# G32R501 register map
Vendor: Geehy Semiconductor Co., Ltd.; Series: G32R5; File version: 1.0
CPU: CM55 r0p1, little endian, MPU, FPU, double-precision FPU, DSP, VTOR, 4 interrupt priority bits
Registers are 32-bit, read-write, reset 0x0 unless marked. A register's access mark holds for its fields unless they carry their own. Offsets are from the block's base; [hi:lo] are bit positions; {n}, {i} and the like mark numbered series.

## FLB1_DATAEXCH — FLB_DATA_EXCHANGE_REGS Registers
Base 0x50102400
Same registers: FLB2_DATAEXCH 0x50102C00, FLB3_DATAEXCH 0x50103400, FLB4_DATAEXCH 0x50103C00
0x00 FLB_PUSH1 ro — FLB PUSH FIFO Registers (from HLC)
  [31:0] PUSH
0x04 FLB_PUSH2 ro — FLB PUSH FIFO Registers (from HLC)
  [31:0] PUSH
0x08 FLB_PUSH3 ro — FLB PUSH FIFO Registers (from HLC)
  [31:0] PUSH
0x0C FLB_PUSH4 ro — FLB PUSH FIFO Registers (from HLC)
  [31:0] PUSH
{0x1FC+4i} FLB_PULL{i} (i=1..4) — FLB PULL FIFO Registers (TO HLC)
  [31:0] PULL

## TMR0 — Timer
Base 0x50110000
Same registers: TMR1 0x50110400, TMR2 0x50110800
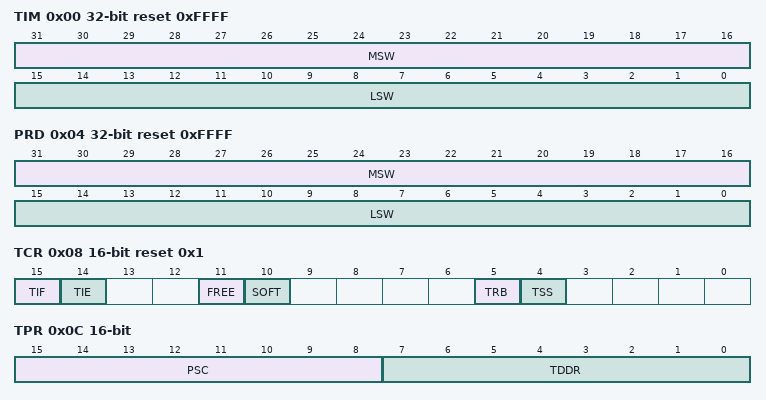
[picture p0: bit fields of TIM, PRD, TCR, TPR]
0x00 TIM reset 0xFFFF — Timer Counter Register
  [31:16] MSW — Timer Counter Registers
  [15:0] LSW — Timer Counter Registers
0x04 PRD reset 0xFFFF — Timer Period Register
  [31:16] MSW — Timer Period Registers
  [15:0] LSW — Timer Period Registers
0x08 TCR 16-bit reset 0x1 — Timer Control Register
  [15] TIF — Timer Overflow Flag
  [14] TIE — Timer Interrupt Enable
  [11] FREE — Emulation modes bit
  [10] SOFT — Emulation modes bit
  [5] TRB — Timer reload
  [4] TSS — Timer stop status bit
0x0C TPR 16-bit access per field — Timer Prescale Register Low
  [15:8] PSC ro — Timer Prescale Counter
  [7:0] TDDR rw — Timer Divide-Down
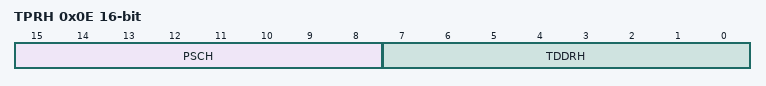
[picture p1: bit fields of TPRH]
0x0E TPRH 16-bit access per field — Timer Prescale Register High
  [15:8] PSCH ro — Timer Prescale Counter
  [7:0] TDDRH rw — Timer Divide-Down

## ADCARESULT — Analog-to-digital converter
Base 0x40020100
Same registers: ADCBRESULT 0x40020500, ADCCRESULT 0x40020900
{0x0+2i} ADCRESULT{i} 16-bit ro (i=0..15)
  [15:0] RESULT — ADC Result {i}
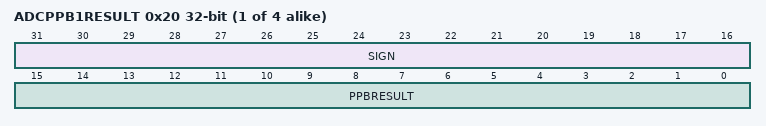
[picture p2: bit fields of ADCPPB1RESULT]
{0x1C+4i} ADCPPB{i}RESULT ro (i=1..4) — ADC Post Processing Block {i} Result Register
  [31:16] SIGN — Sign Extended Bits
  [15:0] PPBRESULT — ADC Post Processing Block Result {i}

## DACA — DAC
Base 0x50001800
Same registers: DACB 0x50001C00
0x00 DACREV 16-bit ro — DAC Revision Register
  [7:0] REV — DAC Revision
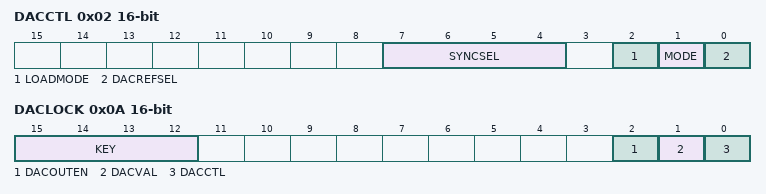
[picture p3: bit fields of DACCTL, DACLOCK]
0x02 DACCTL 16-bit — DAC Control Register
  [7:4] SYNCSEL — DAC EPWMSYNCPER Select
  [2] LOADMODE — DACVALA Load Mode
  [1] MODE — DAC Mode Select
  [0] DACREFSEL — DAC Reference Select
0x04 DACVALA 16-bit ro — DAC Value Register - Active
  [11:0] DACVALA — DAC Active Output Code
0x06 DACVALS 16-bit — DAC Value Register - Shadow
  [11:0] DACVALS — DAC Shadow Output Code
0x08 DACOUTEN 16-bit — DAC Output Enable Register
  [0] DACOUTEN — DAC Output Enable
0x0A DACLOCK 16-bit
  [15:12] KEY — DAC Register Lock Key
  [2] DACOUTEN — DAC Output Enable Register Lock
  [1] DACVAL — DAC Value Register Lock
  [0] DACCTL — DAC Control Register Lock
0x0C DACTRIM 16-bit
  [7:0] OFFSETTRIM — DAC Offset Trim

## SPIA — SPI
Base 0x50001000
Same registers: SPIB 0x50100400
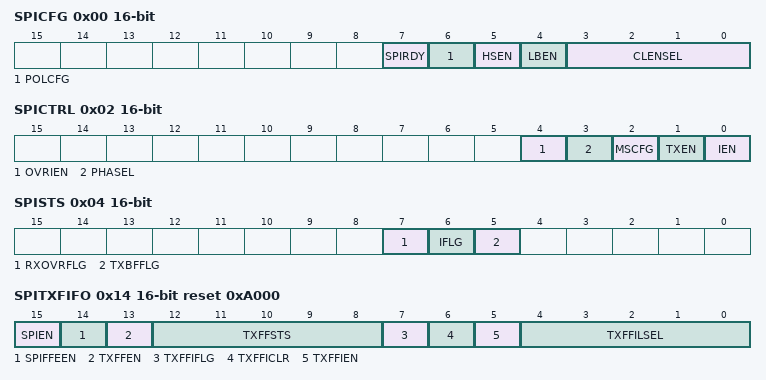
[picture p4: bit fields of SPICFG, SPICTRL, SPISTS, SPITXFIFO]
0x00 SPICFG 16-bit — SPI Configuration Control Register
  [7] SPIRDY — SPI ready
  [6] POLCFG — Clock Polarity Configure
  [5] HSEN — High Speed Mode Enable
  [4] LBEN — Loopback Mode Enable
  [3:0] CLENSEL — Character Length select
0x02 SPICTRL 16-bit — SPI Operation Control Register
  [4] OVRIEN — Overrun Interrupt Enable
  [3] PHASEL — Clock Phase Select
  [2] MSCFG — Master Slave mode configure
  [1] TXEN — Transmit Enable
  [0] IEN — SPI Interrupt Enable
0x04 SPISTS 16-bit access per field — SPI Status Register
  [7] RXOVRFLG wo — Receiver Overrun Flag
  [6] IFLG ro — Interrupt Flag
  [5] TXBFFLG ro — Transmit Buffer Full Flag
0x08 SPIBR 16-bit — SPI Baud Rate Register
  [6:0] BRSEL — Baud Rate selcet
0x0C SPIEMUB 16-bit ro — SPI Emulation Buffer Register
  [15:0] EMUB — Emulation Buffer
0x0E SPIRXB 16-bit ro — SPI Serial Input Buffer Register
  [15:0] RXB — Received Buffer
0x10 SPITXB 16-bit — SPI Serial Output Buffer Register
  [15:0] TXB — Transmit Buffer
0x12 SPISDATAS 16-bit — SPI Serial Data Register
  [15:0] SDATAS — Serial Data Shift
0x14 SPITXFIFO 16-bit access per field reset 0xA000 — SPI FIFO Transmit Register
  [15] SPIEN rw — SPI Enable
  [14] SPIFFEEN rw — SPI FIFO Enhancements enable
  [13] TXFFEN rw — transmit FIFO enable
  [12:8] TXFFSTS ro — transmit FIFO status
  [7] TXFFIFLG ro — Transmit FIFO interrupt flag
  [6] TXFFICLR wo — Transmit FIFO Interrupt Flag Clear
  [5] TXFFIEN rw — Transmit FIFO Interrupt Enable
  [4:0] TXFFILSEL rw — Transmit FIFO interrupt level Selcet
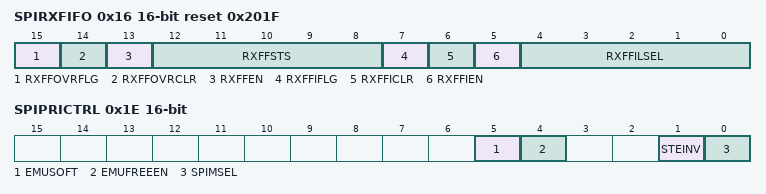
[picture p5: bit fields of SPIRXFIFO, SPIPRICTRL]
0x16 SPIRXFIFO 16-bit access per field reset 0x201F — SPI FIFO Receive Register
  [15] RXFFOVRFLG ro — Receive FIFO Overflow Flag
  [14] RXFFOVRCLR wo — Receive FIFO Overflow Flag Clear
  [13] RXFFEN rw — Receive FIFO enable
  [12:8] RXFFSTS ro — Receive FIFO status
  [7] RXFFIFLG ro — Receive FIFO interrupt flag
  [6] RXFFICLR wo — Receive FIFO Interrupt Flag Clear
  [5] RXFFIEN rw — Receive FIFO Interrupt Enable
  [4:0] RXFFILSEL rw — Receive FIFO interrupt level Selcet
0x18 SPIFFCTRL 16-bit — SPI FIFO Control Register
  [7:0] FFTXDLYSEL — FIFO Transmit Delay Bits
0x1E SPIPRICTRL 16-bit — SPI Priority Control Register
  [5] EMUSOFT — Emulation Soft Run
  [4] EMUFREEEN — Emulation Free Run Enable
  [1] STEINV — STEn Inversion
  [0] SPIMSEL — SPI Mode Selcet
